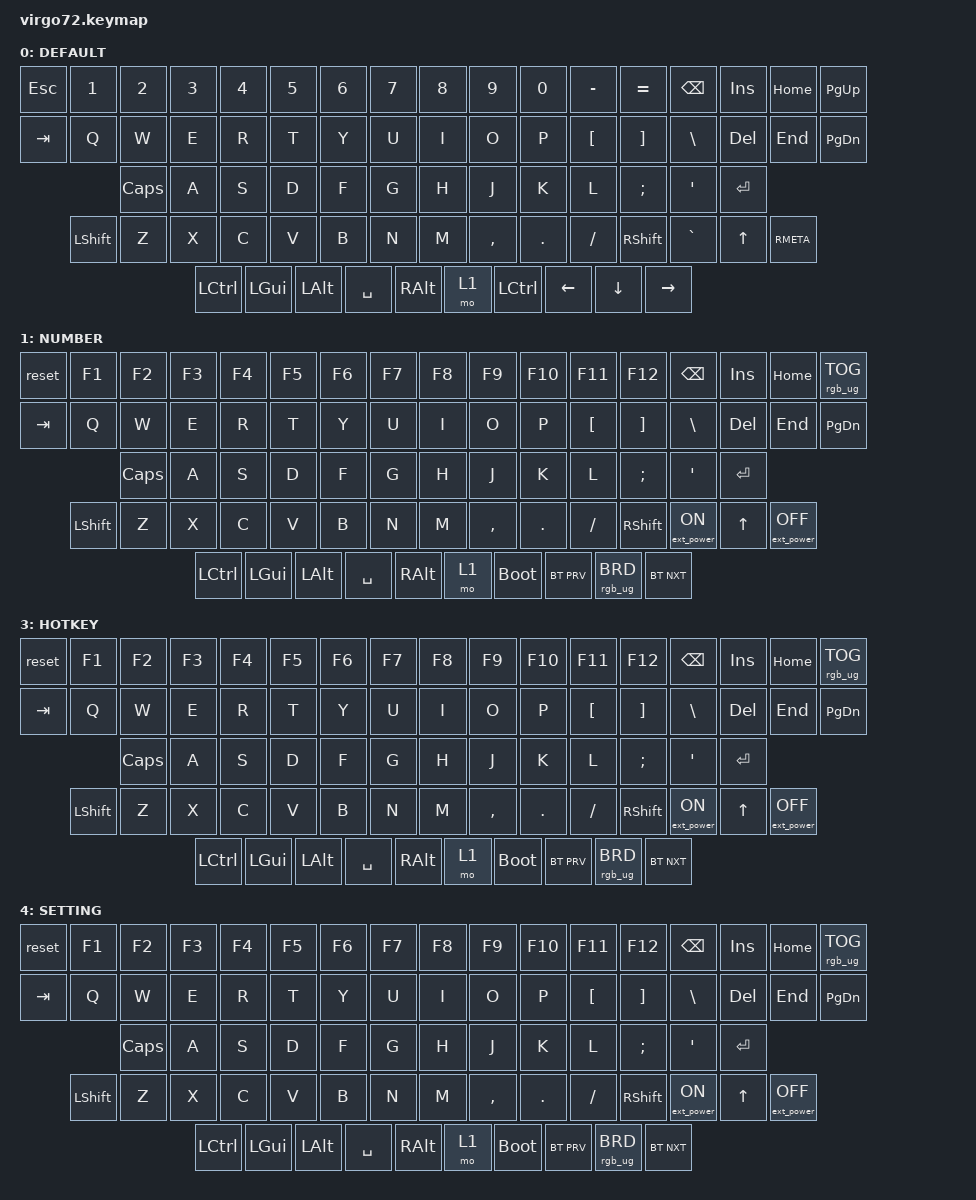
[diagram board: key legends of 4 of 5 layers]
/*
 * Copyright (c) 2022 The ZMK Contributors
 *
 * SPDX-License-Identifier: MIT
 */

#include <behaviors.dtsi>
#include <dt-bindings/zmk/keys.h>
#include <dt-bindings/zmk/bt.h>
#include <dt-bindings/zmk/rgb.h>

#define DEFAULT 0  //默认层
#define NUMBER  1  //第二层
#define SYMBOL  2  //第三层
#define HOTKEY  3  //第四层
#define SETTING 4  //第五层

/ {       //一下是宏功能
        // behaviors {
	// 	macro_phone: macro_1 {//电话号码宏
	// 		compatible = "zmk,behavior-macro";
	// 		label = "MACRO_PHONE";
	// 		#binding-cells = <0>;
	// 		bindings = <&kp N1>, <&kp N9>, <&kp N9>, <&kp N5>, <&kp N7>, 
        //                            <&kp N3>, <&kp N4>, <&kp N2>, <&kp N2>, <&kp N5>, <&kp N8>;
	// 	};
        //         macro_email: macro_2 {//邮箱地址宏
	// 		compatible = "zmk,behavior-macro";
	// 		label = "MACRO_EMAIL";
	// 		#binding-cells = <0>;
	// 		bindings = <&kp 7>, <&kp 1>, <&kp 9>, <&kp 5>, <&kp 3>, <&kp 9>, <&kp 0>, 
        //                            <&kp 6>, <&kp 3>, <&kp AT>, <&kp Q>, <&kp Q>, <&kp DOT>, <&kp C>, <&kp O>, <&kp M>;
	// 	};
        //         macro_pass: macro_3 {//地址宏
	// 		compatible = "zmk,behavior-macro";
	// 		label = "MACRO_PASS";
	// 		#binding-cells = <0>;
	// 		bindings = <&kp LS(C)>, <&kp H>, <&kp E>, <&kp N>, <&kp Z>, <&kp H>, <&kp I>, 
        //                            <&kp H>, <&kp A>, <&kp O>, <&kp N8>, <&kp DOT>, <&kp N1>, <&kp N1>;
	// 	};
	// };
//&kp LS(C)   LS=left shift   +c   等于大写的C
        keymap {
                compatible = "zmk,keymap";

        default_layer {
//&kp TAB 相当于QMK里的KC_TAB
//&mt RSHIFT RET ：单击这个按键是后面的RET（回车），长按是前面的RSHIFT键
//&lt NUMBER SPACE :单击是SPACE键，长按是临时切换到NUMBER层，松开回到默认层
//&none : 这个按键为空
//&trans : 保持和上一层同个按键一样的键值
//&mo SETTING :同QMK的MO，临时切层到SETTING层
//&reset  :软复位
// -------------------------------------------------------------------------------------
// |  Q  |  W  |  E  |
// |  A  |  S  |  D  |
// &bt BT_CLR 无法链接蓝牙是用这个清除
        label = "DEFAULT";  //屏幕显示DEFAULT，下同
// -------------------------------------------------------------------------------------
// |  ESC |  ~  |  1  |  2 |  3  |  4  |  5  | 6 |      |  7  |  8  |  9   | 10 |   -  |   =  |  BKSP |
// |  INS | TAB |  Q  |  W |  E  |  R  |  T  | Y |      |  U  |  I  |  O   |  P |   [  |   ]  |   \   |
// |  DEL |CAPS |  A  |  S |  D  |  F  |  G  | H |      |  J  |  K  |  L   |  ; |   '  |      | ENTER |
// |      |SHIFT|  Z  |  X |  C  |  V  |  B  | B |      |  N  |  M  |  ,   |  . |   ?  |  UP  | SHIFT |
// |      |CTRL | WIN |    | ALT |     |SPACE|   |      |SPACE|     |NUMBER|    | LEFT | DOWN | RIGHT |
        bindings = <
  &kp ESC   &kp N1   &kp N2   &kp N3 &kp N4 &kp N5 &kp N6    &kp N7 &kp N8    &kp N9  &kp N0    &kp MINUS &kp EQUAL &kp BSPC   &kp INSERT &kp HOME &kp PG_UP
	&kp TAB   &kp Q    &kp W    &kp E  &kp R  &kp T  &kp Y     &kp U  &kp I     &kp O   &kp P     &kp LBKT  &kp RBKT  &kp BSLH   &kp DEL    &kp END  &kp PG_DN
	&kp CLCK  &kp A    &kp S    &kp D  &kp F  &kp G  &kp H     &kp J  &kp K     &kp L   &kp SEMI  &kp SQT             &kp RET                
	&kp LSHFT &kp Z    &kp X    &kp C  &kp V  &kp B  &kp N     &kp M  &kp COMMA &kp DOT &kp FSLH                      &kp RSHFT  &kp GRAVE  &kp UP   &kp RMETA
	&kp LCTRL &kp LGUI &kp LALT                      &kp SPACE                          &kp RALT            &mo 1     &kp LCTRL  &kp LEFT   &kp DOWN &kp RIGHT
			>;
                     };

                number_layer {


        label = "NUMBER";
// -------------------------------------------------------------------------------------
// |  ESC |  ~  |  1  |  2 |  3  |  4  |  5  | 6 |      |  7  |  8  |  9   | 10 |   -  |   =  |  BKSP |
// |  INS | TAB |  Q  |  W |  E  |  R  |  T  | Y |      |  U  |  I  |  O   |  P |   [  |   ]  |   \   |
// |  DEL |CAPS |  A  |  S |  D  |  F  |  G  | H |      |  J  |  K  |  L   |  ; |   '  |      | ENTER |
// |      |SHIFT|  Z  |  X |  C  |  V  |  B  | B |      |  N  |  M  |  ,   |  . |   ?  |  UP  | SHIFT |
// |      |CTRL | WIN |    | ALT |     |SPACE|   |      |SPACE|     |NUMBER|    | LEFT | DOWN | RIGHT |
        bindings = <
  &reset    &kp F1   &kp F2   &kp F3 &kp F4 &kp F5 &kp F6    &kp F7 &kp F8    &kp F9  &kp F10   &kp F11   &kp F12   &kp BSPC   &kp INSERT &kp HOME &rgb_ug RGB_TOG
	&kp TAB   &kp Q    &kp W    &kp E  &kp R  &kp T  &kp Y     &kp U  &kp I     &kp O   &kp P     &kp LBKT  &kp RBKT  &kp BSLH   &kp DEL    &kp END  &kp PG_DN
	&kp CLCK  &kp A    &kp S    &kp D  &kp F  &kp G  &kp H     &kp J  &kp K     &kp L   &kp SEMI  &kp SQT             &kp RET                
	&kp LSHFT &kp Z    &kp X    &kp C  &kp V  &kp B  &kp N     &kp M  &kp COMMA &kp DOT &kp FSLH                      &kp RSHFT  &ext_power EP_ON  &kp UP   &ext_power EP_OFF
	&kp LCTRL &kp LGUI &kp LALT                      &kp SPACE                          &kp RALT            &mo 1     &bootloader  &bt BT_PRV &rgb_ug RGB_BRD &bt BT_NXT
			>;
                     };

                symbol_layer {

        label = "SYMBOL";
// -------------------------------------------------------------------------------------
// |  ESC |  ~  |  1  |  2 |  3  |  4  |  5  | 6 |      |  7  |  8  |  9   | 10 |   -  |   =  |  BKSP |
// |  INS | TAB |  Q  |  W |  E  |  R  |  T  | Y |      |  U  |  I  |  O   |  P |   [  |   ]  |   \   |
// |  DEL |CAPS |  A  |  S |  D  |  F  |  G  | H |      |  J  |  K  |  L   |  ; |   '  |      | ENTER |
// |      |SHIFT|  Z  |  X |  C  |  V  |  B  | B |      |  N  |  M  |  ,   |  . |   ?  |  UP  | SHIFT |
// |      |CTRL | WIN |    | ALT |     |SPACE|   |      |SPACE|     |NUMBER|    | LEFT | DOWN | RIGHT |
        bindings = <
  &trans     &trans         &bt BT_SEL 0   &bt BT_SEL 1   &bt BT_SEL 2  &bt BT_SEL 3   &bt BT_SEL 4   &trans         &trans     &trans     &trans       &trans     &trans       &trans       &trans      
  &trans     &trans         &trans         &trans         &trans        &trans         &trans         &trans         &trans     &trans     &trans       &trans     &trans       &trans       &trans
  &trans     &trans         &trans         &trans         &trans        &trans         &trans         &trans         &trans     &trans     &trans       &trans     &trans                    &trans
             &trans         &trans         &trans         &bt BT_CLR    &trans         &trans         &trans         &trans     &trans     &trans       &trans     &trans       &trans       &trans
             &trans         &trans                        &trans                       &trans                        &trans                &trans                  &trans       &trans       &trans
                        >;
                };

                hotkey_layer {
// -----------------------------------------------------------------------------------------
// |   |   |   |   |   |   |     |   |   |   |   |   |   |
// |   |   |   |   |   |   |     |   |   |   |   |   |   |
// |   |   |   |   |   |   |     |   |   |   |   |   |   |
//             |     |     |     |     |     |
        label = "HOTKEY";
        bindings = <
 &reset    &kp F1   &kp F2   &kp F3 &kp F4 &kp F5 &kp F6    &kp F7 &kp F8    &kp F9  &kp F10   &kp F11   &kp F12   &kp BSPC   &kp INSERT &kp HOME &rgb_ug RGB_TOG
	&kp TAB   &kp Q    &kp W    &kp E  &kp R  &kp T  &kp Y     &kp U  &kp I     &kp O   &kp P     &kp LBKT  &kp RBKT  &kp BSLH   &kp DEL    &kp END  &kp PG_DN
	&kp CLCK  &kp A    &kp S    &kp D  &kp F  &kp G  &kp H     &kp J  &kp K     &kp L   &kp SEMI  &kp SQT             &kp RET                
	&kp LSHFT &kp Z    &kp X    &kp C  &kp V  &kp B  &kp N     &kp M  &kp COMMA &kp DOT &kp FSLH                      &kp RSHFT  &ext_power EP_ON  &kp UP   &ext_power EP_OFF
	&kp LCTRL &kp LGUI &kp LALT                      &kp SPACE                          &kp RALT            &mo 1     &bootloader  &bt BT_PRV &rgb_ug RGB_BRD &bt BT_NXT
			>;
                };
                
// -----------------------------------------------------------------------------------------
// |    | RGB BRI+ | RGB SAT+ | RGB HUE+ | RGB ANI+ | RGB TOG |   | BT1 | BT2 | BT3 | BT4 | BT5 | BT CLR |
// |    | RGB BRI- | RGB SAT- | RGB HUE- | RGB ANI- |         |   | LEFT| UP  | DOWN|RIGHT|     |        |
// |    |  RESET   |          |          |  RESET   |         |   | HOME| END |     |     |     |        |
//                                              |     |     |     |     |     |
                  setting_layer {
        label = "SETTING";
        bindings = <
 &reset    &kp F1   &kp F2   &kp F3 &kp F4 &kp F5 &kp F6    &kp F7 &kp F8    &kp F9  &kp F10   &kp F11   &kp F12   &kp BSPC   &kp INSERT &kp HOME &rgb_ug RGB_TOG
	&kp TAB   &kp Q    &kp W    &kp E  &kp R  &kp T  &kp Y     &kp U  &kp I     &kp O   &kp P     &kp LBKT  &kp RBKT  &kp BSLH   &kp DEL    &kp END  &kp PG_DN
	&kp CLCK  &kp A    &kp S    &kp D  &kp F  &kp G  &kp H     &kp J  &kp K     &kp L   &kp SEMI  &kp SQT             &kp RET                
	&kp LSHFT &kp Z    &kp X    &kp C  &kp V  &kp B  &kp N     &kp M  &kp COMMA &kp DOT &kp FSLH                      &kp RSHFT  &ext_power EP_ON  &kp UP   &ext_power EP_OFF
	&kp LCTRL &kp LGUI &kp LALT                      &kp SPACE                          &kp RALT            &mo 1     &bootloader  &bt BT_PRV &rgb_ug RGB_BRD &bt BT_NXT
			>;
                };
        };
};
